# STM32WBA52 register map
File version: 0.1
CPU: CM33 r0p1, little endian, MPU, FPU, 4 interrupt priority bits
Registers are 32-bit, read-write, reset 0x0 unless marked. A register's access mark holds for its fields unless they carry their own. Offsets are from the block's base; [hi:lo] are bit positions.

## RCC (part 1 of 3) — Reset and clock control
Base 0x46020C00
Same registers: SEC_RCC 0x56020C00
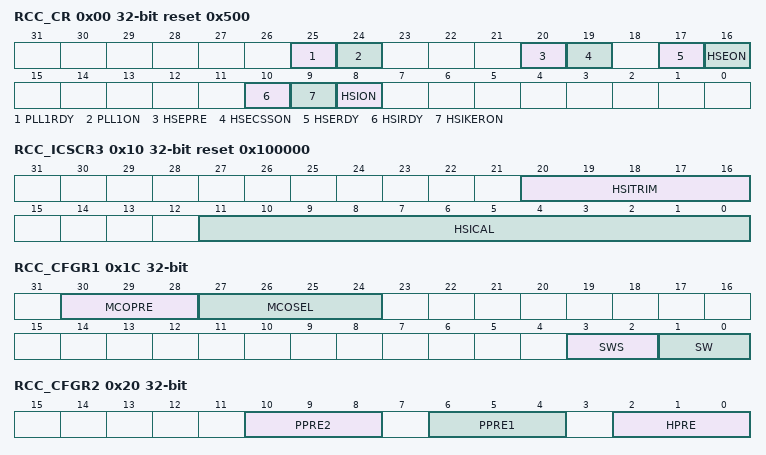
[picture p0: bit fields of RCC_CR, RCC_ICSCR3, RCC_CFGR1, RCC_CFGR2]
0x00 RCC_CR access per field reset 0x500 — RCC clock control register
  [25] PLL1RDY ro — PLL1 clock ready flag Set by hardware to indicate that the PLL1 is locked. Access to the bit can be secured by RCC PLL1SEC. When secure, a non-secure read/write access is RAZ/WI. It does not generate an illegal access interrupt. This bit can be protected against unprivileged access when secure with RCC SPRIV or when non-secure with RCC NSPRIV.
    0=PLL1 unlocked; 1=PLL1 locked (PLL1RDY remains set when PLL1 is selected as sysclk and PLL1 is disabled by HSECSS failure)
  [24] PLL1ON rw — PLL1 enable Set and cleared by software to enable the main PLL. Cleared by hardware when entering Stop or Standby modes and when PLL1 on HSE32 is selected as sysclk, on a HSECSS failure. This bit cannot be reset if the PLL1 clock is used as the system clock. Access to the bit can be secured by RCC PLL1SEC. When secure, a non-secure read/write access is RAZ/WI. It does not generate an illegal access interrupt. This bit can be protected against unprivileged access when secure with RCC SPRIV or when non-secure with RCC NSPRIV.
    0=PLL1 off; 1=PLL1 on
  [20] HSEPRE rw — HSE32 clock for SYSCLK prescaler Set and cleared by software to control the division factor of the HSE32 clock for SYSCLK. Access to the bit can be secured by RCC HSESEC. When secure, a non-secure read/write access is RAZ/WI. It does not generate an illegal access interrupt. This bit can be protected against unprivileged access when secure with RCC SPRIV or when non-secure with RCC NSPRIV.
    0=HSE32 not divided, SYSCLK = HSE32; 1=HSE32 divided, SYSCLK = HSE32/2
  [19] HSECSSON rw — HSE32 clock security system enable Set by software to enable the HSE32 clock security system. When HSECSSON is set, the clock detector is enabled by hardware when the HSE32 oscillator is ready and disabled by hardware if a HSE32 clock failure is detected. This bit is set only and is cleared by reset. Access to the bit can be secured by RCC HSESEC. When secure, a non-secure read/write access is RAZ/WI. It does not generate an illegal access interrupt. This bit can be protected against unprivileged access when secure with RCC SPRIV or when non-secure with RCC NSPRIV.
    0=HSE32 clock security system off (clock detector off); 1=HSE32 clock security system on (clock detector on if the HSE32 oscillator is stable, off if not)
  [17] HSERDY ro — HSE32 clock ready flag Set by hardware to indicate that the HSE32 oscillator is stable. This bit is set both when HSE32 is enabled by software by setting HSEON and when requested as kernel clock by the 2.4 GHz RADIO. Access to the bit can be secured by RCC HSESEC. When secure, a non-secure read/write access is RAZ/WI. It does not generate an illegal access interrupt. This bit can be protected against unprivileged access when secure with RCC SPRIV or when non-secure with RCC NSPRIV.
    0=HSE32 oscillator not ready; 1=HSE32 oscillator ready to be used by the CPU (HSERDY remains set when HSE32 is disabled by HSECSS failure)
  [16] HSEON rw — HSE32 clock enable Set and cleared by software. Cleared by hardware to stop the HSE32 clock for the CPU when entering Stop and Standby modes and on a HSECSS failure. When the HSE32 is used as 2.4 GHz RADIO kernel clock, enabled by RADIOEN and RADIOSMEN and the 2.4 GHz RADIO is active, HSEON is not be cleared when entering low power mode. In this case only Stop 0 mode is entered as low power mode. This bit cannot be reset if the HSE32 oscillator is used directly or indirectly as the system clock. Access to the bit can be secured by RCC HSESEC. When secure, a non-secure read/write access is RAZ/WI. It does not generate an illegal access interrupt. This bit can be protected against unprivileged access when secure with RCC SPRIV or when non-secure with RCC NSPRIV.
    0=HSE32 oscillator not requested by the CPU; 1=HSE32 oscillator ON
  [10] HSIRDY ro — HSI16 clock ready flag Set by hardware to indicate that HSI16 oscillator is stable. This bit is set only when HSI16 is enabled by software by setting HSION. Access to the bit can be secured by RCC HSISEC. When secure, a non-secure read/write access is RAZ/WI. It does not generate an illegal access interrupt. This bit can be protected against unprivileged access when secure with RCC SPRIV or when non-secure with RCC NSPRIV. Note: Once the HSION bit is cleared, HSIRDY goes low after six HSI16 clock cycles.
    0=HSI16 oscillator not ready; 1=HSI16 oscillator ready
  [9] HSIKERON rw — HSI16 enable for some peripheral kernels Set and cleared by software to force HSI16 oscillator on even in Stop modes. Keeping the HSI16 oscillator on in Stop modes allows the communication speed not to be reduced by the HSI16 oscillator startup time. This bit has no effect on register bit HSION value. Cleared by hardware when entering Standby modes. Refer to Peripherals clock gating and autonomous mode for more details. Access to the bit can be secured by RCC HSISEC. When secure, a non-secure read/write access is RAZ/WI. It does not generate an illegal access interrupt. This bit can be protected against unprivileged access when secure with RCC SPRIV or when non-secure with RCC NSPRIV.
    0=No effect on HSI16 oscillator; 1=HSI16 oscillator forced on even in Stop mode
  [8] HSION rw — HSI16 clock enable Set and cleared by software. Cleared by hardware when entering Stop and Standby modes. Set by hardware to force the HSI16 oscillator on when exiting Stop and Standby modes. Set by hardware to force the HSI16 oscillator on in case of clock security failure of the HSE32 crystal oscillator. This bit is set by hardware if the HSI16 is used directly or indirectly as system clock. Access to the bit can be secured by RCC HSISEC. When secure, a non-secure read/write access is RAZ/WI. It does not generate an illegal access interrupt. This bit can be protected against unprivileged access when secure with RCC SPRIV or when non-secure with RCC NSPRIV.
    0=HSI16 oscillator off; 1=HSI16 oscillator on
0x10 RCC_ICSCR3 access per field reset 0x100000 (reset mask 0xFFFFF000) — RCC internal clock sources calibration register 3
  [20:16] HSITRIM rw — HSI16 clock trimming These bits provide an additional user-programmable trimming value that is added to the HSICAL[11:0] bits. It can be programmed to adjust to voltage and temperature variations that influence the frequency of the HSI16.
  [11:0] HSICAL ro — HSI16 clock calibration These bits are initialized at startup with the factory-programmed HSI16 calibration value. When HSITRIM[4:0] is written, HSICAL[11:0] is updated with the sum of HSITRIM[4:0] and the initial factory trim value.
0x1C RCC_CFGR1 access per field — RCC clock configuration register 1
  [30:28] MCOPRE rw — microcontroller clock output prescaler Set and cleared by software. It is highly recommended to change this prescaler before MCO output is enabled. others: not allowed
    0=MCO divided by 1; 1=MCO divided by 2; 2=MCO divided by 4; 3=MCO divided by 8; 4=MCO divided by 16
  [27:24] MCOSEL rw — microcontroller clock output Set and cleared by software. others: reserved Note: This clock output may have some truncated cycles at startup or during MCO clock source switching.
    0=MCO output disabled, no clock on MCO; 1=sysclkpre system clock after PLL1RCLKPRE division selected; 3=HSI16 clock selected; 4=HSE32 clock selected; 5=pll1rclk clock selected; 6=LSI clock selected; 7=LSE clock selected; 8=pll1pclk clock selected; 9=pll1qclk clock selected; 10=hclk5 clock selected
  [3:2] SWS ro — system clock switch status Set and cleared by hardware to indicate which clock source is used as system clock.
    0=HSI16 oscillator used as system clock; 2=HSE32 or HSE32/2, as defined by HSEPRE, used as system clock; 3=pll1rclk used as system clock
  [1:0] SW rw — system clock switch Set and cleared by software to select system clock source (SYSCLK). Cleared by hardware when entering Stop and Standby modes When selecting HSE32 directly or indirectly as system clock and HSE32 oscillator clock security fails, cleared by hardware.
    0=HSI16 selected as system clock; 2=HSE32 or HSE32/2, as defined by HSEPRE, selected as system clock; 3=pll1rclk selected as system clock
0x20 RCC_CFGR2 — RCC clock configuration register 2
  [10:8] PPRE2 — APB2 prescaler Set and cleared by software to control the division factor of the APB2 clock (pclk2). 0xx: pclk2 = hclk1 not divided
    4=pclk2 = hclk1 divided by 2; 5=pclk2 = hclk1 divided by 4; 6=pclk2 = hclk1 divided by 8; 7=pclk2 = hclk1 divided by 16
  [6:4] PPRE1 — APB1 prescaler Set and cleared by software to control the division factor of the APB1 clock (pclk1). 0xx: pclk1 = hclk1 not divided
    4=pclk1 = hclk1 divided by 2; 5=pclk1 = hclk1 divided by 4; 6=pclk1 = hclk1 divided by 8; 7=pclk1 = hclk1 divided by 16
  [2:0] HPRE — AHB1, AHB2 and AHB4 prescaler Set and cleared by software to control the division factor of the AHB1, AHB2 and AHB4 clock (hclk1). The software must limit the incremental frequency step by setting these bits correctly to ensure that the hclk1 maximum incremental frequency step does not exceed the maximum allowed incremental frequency step (for more details, refer to Table�99: SYSCLK and bus maximum frequency). After a write operation to these bits and before decreasing the voltage range, this register must be read to be sure that the new value is taken into account. 0xx: hclk1 = SYSCLK not divided
    4=hclk1 = SYSCLK divided by 2; 5=hclk1 = SYSCLK divided by 4; 6=hclk1 = SYSCLK divided by 8; 7=hclk1 = SYSCLK divided by 16
0x24 RCC_CFGR3 — RCC clock configuration register 3
  [6:4] PPRE7 — APB7 prescaler Set and cleared by software to control the division factor of the APB7 clock (pclk7). 0xx: hclk1 not divided
    4=hclk1 divided by 2; 5=hclk1 divided by 4; 6=hclk1 divided by 8; 7=hclk1 divided by 16
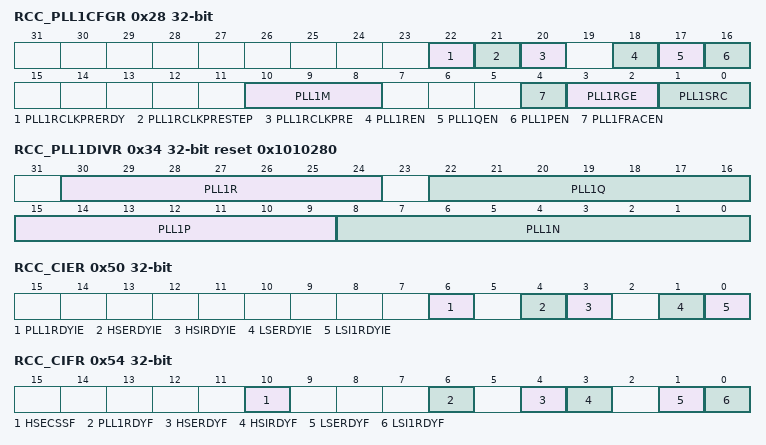
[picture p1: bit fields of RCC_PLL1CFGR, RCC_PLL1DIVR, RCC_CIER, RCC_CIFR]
0x28 RCC_PLL1CFGR access per field — RCC PLL1 configuration register
  [22] PLL1RCLKPRERDY ro — pll1rclkpre not divided ready. Set by hardware after PLL1RCLKPRE has been set from divided to not divide, to indicate that the pll1rclk not divided is available on sysclkpre.
    0=pll1rclk divided; 1=pll1rclk not divided ready
  [21] PLL1RCLKPRESTEP rw — pll1rclk clock for SYSCLK prescaler division step selection Set and cleared by software to control the division step of the pll1rclk clock for SYSCLK.
    0=pll1rclk 2-step division; 1=pll1rclk 3-step division
  [20] PLL1RCLKPRE rw — pll1rclk clock for SYSCLK prescaler division enable Set and cleared by software to control the division of the pll1rclk clock for SYSCLK.
    0=pll1rclk not divided, sysclkpre = pll1rclk; 1=pll1rclk divided, sysclkpre = pll1rclk divided
  [18] PLL1REN rw — PLL1 DIVR divider output enable Set and cleared by software to enable the pll1rclk output of the PLL1. To save power, PLL1REN and PLL1R bits must be set to 0 when the pll1rclk is not used. This bit can be written only when the PLL1 is disabled (PLL1ON = 0 and PLL1RDY = 0).
    0=pll1rclk output disabled; 1=pll1rclk output enabled
  [17] PLL1QEN rw — PLL1 DIVQ divider output enable Set and reset by software to enable the pll1qclk output of the PLL1. To save power, PLL1QEN and PLL1Q bits must be set to 0 when the pll1qclk is not used. This bit can be written only when the PLL1 is disabled (PLL1ON = 0 and PLL1RDY = 0).
    0=pll1qclk output disabled; 1=pll1qclk output enabled
  [16] PLL1PEN rw — PLL1 DIVP divider output enable Set and reset by software to enable the pll1pclk output of the PLL1. To save power, PLL1PEN and PLL1P bits must be set to 0 when the pll1pclk is not used. This bit can be written only when the PLL1 is disabled (PLL1ON = 0 and PLL1RDY = 0).
    0=pll1pclk output disabled; 1=pll1pclk output enabled
  [10:8] PLL1M rw — Prescaler for PLL1 Set and cleared by software to configure the prescaler of the PLL1. The VCO1 input frequency is PLL1 input clock frequency/PLL1M. This bit can be written only when the PLL1 is disabled (PLL1ON = 0 and PLL1RDY = 0). ...
    0=division by 1 (bypass); 1=division by 2; 2=division by 3; 7=division by 8
  [4] PLL1FRACEN rw — PLL1 fractional latch enable Set and reset by software to latch the content of PLL1FRACN into the ΣΔ modulator. In order to latch the PLL1FRACN value into the ΣΔ modulator, PLL1FRACEN must be set to 0, then set to 1: the transition 0 to 1 transfers the content of PLL1FRACN into the modulator (see PLL1 initialization phase for details).
  [3:2] PLL1RGE rw — PLL1 input frequency range Set and reset by software to select the proper reference frequency range used for PLL1. This bit must be written before enabling the PLL1. 00-01-10: PLL1 input (ref1_ck) clock range frequency between 4 and 8 MHz
    3=PLL1 input (ref1_ck) clock range frequency between 8 and 16 MHz
  [1:0] PLL1SRC rw — PLL1 entry clock source Set and cleared by software to select PLL1 clock source. These bits can be written only when the PLL1 is disabled. Cleared by hardware when entering Stop or Standby modes. Note: In order to save power, when no PLL1 clock is used, the value of PLL1SRC must be 0.
    0=no clock sent to PLL1; 2=HSI16 clock selected as PLL1 clock entry; 3=HSE32 clock after HSEPRE divider selected as PLL1 clock entry
0x34 RCC_PLL1DIVR reset 0x1010280 — RCC PLL1 dividers register
  [30:24] PLL1R — PLL1 DIVR division factor Set and reset by software to control the frequency of the pll1rclk clock. These bits can be written only when the PLL1 is disabled (PLL1ON = 0 and PLL1RDY = 0). ...
    0=pll1rclk = VCO output frequency; 1=pll1rclk = VCO output frequency / 2 (default after reset); 2=pll1rclk = VCO output frequency / 3; 3=pll1rclk = VCO output frequency / 4; 127=pll1rclk = VCO output frequency / 128
  [22:16] PLL1Q — PLL1 DIVQ division factor Set and reset by software to control the frequency of the PLl1QCLK clock. These bits can be written only when the PLL1 is disabled (PLL1ON = 0 and PLL1RDY = 0). ...
    0=PLl1QCLK = VCO output frequency; 1=PLl1QCLK = VCO output frequency / 2 (default after reset); 2=PLl1QCLK = VCO output frequency / 3; 3=PLl1QCLK = VCO output frequency / 4; 127=PLl1QCLK = VCO output frequency / 128
  [15:9] PLL1P — PLL1 DIVP division factor Set and reset by software to control the frequency of the pll1pclk clock. These bits can be written only when the PLL1 is disabled (PLL1ON = 0 and PLL1RDY = 0). Note that odd division factors are not allowed. ...
    0=Not allowed; 1=pll1pclk = VCO output frequency / 2 (default after reset); 2=not allowed; 3=pll1pclk = VCO output frequency / 4; 127=pll1pclk = VCO output frequency / 128
  [8:0] PLL1N — Multiplication factor for PLL1 VCO Set and reset by software to control the multiplication factor of the VCO. These bits can be written only when the PLL1 is disabled (PLL1ON = 0 and PLL1RDY = 0). ... ... others: reserved VCO output frequency = F<sub>ref1_ck</sub> x multiplication factor for PLL1 VCO, when fractional value 0 has been loaded into PLL1FRACN, with: Multiplication factor for PLL1 VCO between 4 and 512 input frequency F<sub>ref1_ck</sub> between 4 and 16�MHz
    3=multiplication factor for PLL1 VCO= 4; 4=multiplication factor for PLL1 VCO = 5; 5=multiplication factor for PLL1 VCO = 6; 128=multiplication factor for PLL1 VCO = 129 (default after reset); 0x1FF=multiplication factor for PLL1 VCO = 512
0x38 RCC_PLL1FRACR — RCC PLL1 fractional divider register
  [15:3] PLL1FRACN — Fractional part of the multiplication factor for PLL1 VCO Set and reset by software to control the fractional part of the multiplication factor of the VCO. These bits can be written at any time, allowing dynamic fine-tuning of the PLL1 VCO. VCO output frequency = F<sub>ref1_ck</sub> x [multiplication factor for PLL1 VCO + (PLL1FRACN / 2<sup>13</sup>)], with: Multiplication factor for PLL1 VCO must be between 4 and 512. PLL1FRACN can be between 0 and 2<sup>13</sup>- 1. The input frequency F<sub>ref1_ck</sub> must be between 4 and 16 MHz. To change the used fractional value on-the-fly even if the PLL1 is enabled, the application must proceed as follows: Set the bit PLL1FRACEN to 0. Write the new fractional value into PLL1FRACN. Set the bit PLL1FRACEN to 1.
0x50 RCC_CIER — RCC clock interrupt enable register
  [6] PLL1RDYIE — PLL1 ready interrupt enable Set and cleared by software to enable/disable interrupt caused by PLL1 lock. Access to the bit can be secured by RCC PLL1SEC. When secure, a non-secure read/write access is RAZ/WI. It does not generate an illegal access interrupt. This bit can be protected against unprivileged access when secure with RCC SPRIV or when non-secure with RCC NSPRIV.
    0=PLL1 lock interrupt disabled; 1=PLL1 lock interrupt enabled
  [4] HSERDYIE — HSE32 ready interrupt enable Set and cleared by software to enable/disable interrupt caused by the HSE32 oscillator stabilization. Access to the bit can be secured by RCC HSESEC. When secure, a non-secure read/write access is RAZ/WI. It does not generate an illegal access interrupt. This bit can be protected against unprivileged access when secure with RCC SPRIV or when non-secure with RCC NSPRIV.
    0=HSE32 ready interrupt disabled; 1=HSE32 ready interrupt enabled
  [3] HSIRDYIE — HSI16 ready interrupt enable Set and cleared by software to enable/disable interrupt caused by the HSI16 oscillator stabilization. Access to the bit can be secured by RCC HSISEC. When secure, a non-secure read/write access is RAZ/WI. It does not generate an illegal access interrupt. This bit can be protected against unprivileged access when secure with RCC SPRIV or when non-secure with RCC NSPRIV.
    0=HSI16 ready interrupt disabled; 1=HSI16 ready interrupt enabled
  [1] LSERDYIE — LSE ready interrupt enable Set and cleared by software to enable/disable interrupt caused by the LSE oscillator stabilization. Access to the bit can be secured by RCC LSESEC. When secure, a non-secure read/write access is RAZ/WI. It does not generate an illegal access interrupt. This bit can be protected against unprivileged access when secure with RCC SPRIV or when non-secure with RCC NSPRIV.
    0=LSE ready interrupt disabled; 1=LSE ready interrupt enabled
  [0] LSI1RDYIE — LSI1 ready interrupt enable Set and cleared by software to enable/disable interrupt caused by the LSI1 oscillator stabilization. Access to the bit can be secured by RCC LSISEC. When secure, a non-secure read/write access is RAZ/WI. It does not generate an illegal access interrupt. This bit can be protected against unprivileged access when secure with RCC SPRIV or when non-secure with RCC NSPRIV.
    0=LSI1 ready interrupt disabled; 1=LSI1 ready interrupt enabled
0x54 RCC_CIFR ro — RCC clock interrupt flag register
  [10] HSECSSF — HSE32 clock security system interrupt flag Set by hardware when a clock security failure is detected in the HSE32 oscillator. Cleared by software setting the HSECSSC bit. Access to the bit can be secured by RCC HSESEC. When secure, a non-secure read/write access is RAZ/WI. It does not generate an illegal access interrupt. This bit can be protected against unprivileged access when secure with RCC SPRIV or when non-secure with RCC NSPRIV.
    0=no clock security interrupt caused by HSE32 clock failure; 1=clock security interrupt caused by HSE32 clock failure
  [6] PLL1RDYF — PLL1 ready interrupt flag Set by hardware when the PLL1 locks and PLL1RDYIE is set. Cleared by software setting the PLL1RDYC bit. Access to the bit can be secured by RCC PLL1SEC. When secure, a non-secure read/write access is RAZ/WI. It does not generate an illegal access interrupt. This bit can be protected against unprivileged access when secure with RCC SPRIV or when non-secure with RCC NSPRIV.
    0=no clock ready interrupt caused by PLL1 lock; 1=clock ready interrupt caused by PLL1 lock
  [4] HSERDYF — HSE32 ready interrupt flag Set by hardware when the HSE32 clock becomes stable and HSERDYIE is set. Cleared by software setting the HSERDYC bit. Access to the bit can be secured by RCC HSESEC. When secure, a non-secure read/write access is RAZ/WI. It does not generate an illegal access interrupt. This bit can be protected against unprivileged access when secure with RCC SPRIV or when non-secure with RCC NSPRIV.
    0=no clock ready interrupt caused by the HSE32 oscillator; 1=clock ready interrupt caused by the HSE32 oscillator
  [3] HSIRDYF — HSI16 ready interrupt flag Set by hardware when the HSI16 clock becomes stable and HSIRDYIE is set in a response to setting the HSION (see RCC_CR). When HSION is not set but the HSI16 oscillator is enabled by the peripheral through a clock request, this bit is not set and no interrupt is generated. Access to the bit can be secured by RCC HSISEC. When secure, a non-secure read/write access is RAZ/WI. It does not generate an illegal access interrupt. This bit can be protected against unprivileged access when secure with RCC SPRIV or when non-secure with RCC NSPRIV. Cleared by software setting the HSIRDYC bit.
    0=no clock ready interrupt caused by the HSI16 oscillator; 1=clock ready interrupt caused by the HSI16 oscillator
  [1] LSERDYF — LSE ready interrupt flag Set by hardware when the LSE clock becomes stable and LSERDYIE is set. Cleared by software setting the LSERDYC bit. Access to the bit can be secured by RCC LSESEC. When secure, a non-secure read/write access is RAZ/WI. It does not generate an illegal access interrupt. This bit can be protected against unprivileged access when secure with RCC SPRIV or when non-secure with RCC NSPRIV.
    0=no clock ready interrupt caused by the LSE oscillator; 1=clock ready interrupt caused by the LSE oscillator
  [0] LSI1RDYF — LSI1 ready interrupt flag Set by hardware when the LSI1 clock becomes stable and LSI1RDYIE is set. Cleared by software setting the LSI1RDYC bit. Access to the bit can be secured by RCC LSISEC. When secure, a non-secure read/write access is RAZ/WI. It does not generate an illegal access interrupt. This bit can be protected against unprivileged access when secure with RCC SPRIV or when non-secure with RCC NSPRIV.
    0=no clock ready interrupt caused by the LSI1 oscillator; 1=clock ready interrupt caused by the LSI1 oscillator
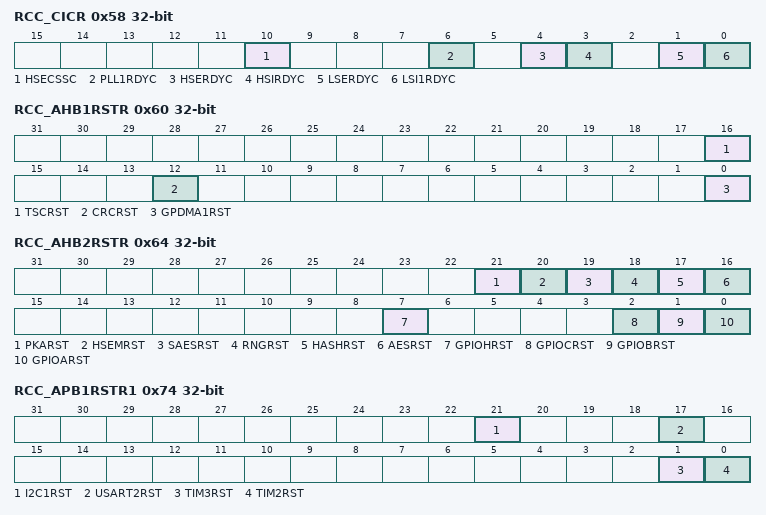
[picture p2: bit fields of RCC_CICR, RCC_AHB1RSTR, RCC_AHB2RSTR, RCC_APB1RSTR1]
0x58 RCC_CICR wo — RCC clock interrupt clear register
  [10] HSECSSC — High speed external clock security system interrupt clear Writing this bit to 1 clears the HSECSSF flag. Writing 0 has no effect. Access to the bit can be secured by RCC HSESEC. When secure, a non-secure read/write access is RAZ/WI. It does not generate an illegal access interrupt. This bit can be protected against unprivileged access when secure with RCC SPRIV or when non-secure with RCC NSPRIV.
  [6] PLL1RDYC — PLL1 ready interrupt clear Writing this bit to 1 clears the PLL1RDYF flag. Writing 0 has no effect. Access to the bit can be secured by RCC PLL1SEC. When secure, a non-secure read/write access is RAZ/WI. It does not generate an illegal access interrupt. This bit can be protected against unprivileged access when secure with RCC SPRIV or when non-secure with RCC NSPRIV.
  [4] HSERDYC — HSE32 ready interrupt clear Writing this bit to 1 clears the HSERDYF flag. Writing 0 has no effect. Access to the bit can be secured by RCC HSESEC. When secure, a non-secure read/write access is RAZ/WI. It does not generate an illegal access interrupt. This bit can be protected against unprivileged access when secure with RCC SPRIV or when non-secure with RCC NSPRIV.
  [3] HSIRDYC — HSI16 ready interrupt clear Writing this bit to 1 clears the HSIRDYF flag. Writing 0 has no effect.\ Access to the bit can be secured by RCC HSISEC. When secure, a non-secure read/write access is RAZ/WI. It does not generate an illegal access interrupt. This bit can be protected against unprivileged access when secure with RCC SPRIV or when non-secure with RCC NSPRIV.
  [1] LSERDYC — LSE ready interrupt clear Writing this bit to 1 clears the LSERDYF flag. Writing 0 has no effect. Access to the bit can be secured by RCC LSESEC. When secure, a non-secure read/write access is RAZ/WI. It does not generate an illegal access interrupt. This bit can be protected against unprivileged access when secure with RCC SPRIV or when non-secure with RCC NSPRIV.
  [0] LSI1RDYC — LSI1 ready interrupt clear Writing this bit to 1 clears the LSI1RDYF flag. Writing 0 has no effect. Access to the bit can be secured by RCC LSISEC. When secure, a non-secure read/write access is RAZ/WI. It does not generate an illegal access interrupt. This bit can be protected against unprivileged access when secure with RCC SPRIV or when non-secure with RCC NSPRIV.
0x60 RCC_AHB1RSTR — RCC AHB1 peripheral reset register
  [16] TSCRST — TSC reset Set and cleared by software. Access can be secured by GTZC_TZSC TSCSEC. When secure, a non-secure read/write access is RAZ/WI. It does not generate an illegal access interrupt. This bit can be protected against unprivileged access when secure with RCC SPRIV or when non-secure with RCC NSPRIV.
    0=No effect; 1=Reset TSC
  [12] CRCRST — CRC reset Set and cleared by software. Access can be secured by GTZC_TZSC CRCSEC. When secure, a non-secure read/write access is RAZ/WI. It does not generate an illegal access interrupt. This bit can be protected against unprivileged access when secure with RCC SPRIV or when non-secure with RCC NSPRIV.
    0=No effect; 1=Reset CRC
  [0] GPDMA1RST — GPDMA1 reset Set and cleared by software. Access can be secured by GPDMA1 SECx. When secure, a non-secure read/write access is RAZ/WI. It does not generate an illegal access interrupt. This bit can be protected against unprivileged access when secure with RCC SPRIV or when non-secure with RCC NSPRIV.
    0=No effect; 1=Reset GPDMA1
0x64 RCC_AHB2RSTR — RCC AHB2 peripheral reset register
  [21] PKARST — PKA reset Set and cleared by software. Access can be secured by GTZC_TZSC PKASEC. When secure, a non-secure read/write access is RAZ/WI. It does not generate an illegal access interrupt. This bit can be protected against unprivileged access when secure with RCC SPRIV or when non-secure with RCC NSPRIV.
    0=No effect; 1=Reset PKA
  [20] HSEMRST — HSEM hardware accelerator reset Set and cleared by software. Can only be accessed secure when one or more features in the HSEM is secure. When secure, a non-secure read/write access is RAZ/WI. It does not generate an illegal access interrupt. This bit can be protected against unprivileged access when secure with RCC SPRIV or when non-secure with RCC NSPRIV.
    0=No effect; 1=Reset HSEM
  [19] SAESRST — SAES hardware accelerator reset Set and cleared by software. Access can be secured by GTZC_TZSC SAESSEC. When secure, a non-secure read/write access is RAZ/WI. It does not generate an illegal access interrupt. This bit can be protected against unprivileged access when secure with RCC SPRIV or when non-secure with RCC NSPRIV.
    0=No effect; 1=Reset SAES
  [18] RNGRST — Random number generator reset Set and cleared by software. Access can be secured by GTZC_TZSC RNGSEC. When secure, a non-secure read/write access is RAZ/WI. It does not generate an illegal access interrupt. This bit can be protected against unprivileged access when secure with RCC SPRIV or when non-secure with RCC NSPRIV.
    0=No effect; 1=Reset RNG
  [17] HASHRST — Hash reset Set and cleared by software. Access can be secured by GTZC_TZSC HASHSEC. When secure, a non-secure read/write access is RAZ/WI. It does not generate an illegal access interrupt. This bit can be protected against unprivileged access when secure with RCC SPRIV or when non-secure with RCC NSPRIV.
    0=No effect; 1=Reset HASH
  [16] AESRST — AES hardware accelerator reset Set and cleared by software. Access can be secured by GTZC_TZSC AESSEC. When secure, a non-secure read/write access is RAZ/WI. It does not generate an illegal access interrupt. This bit can be protected against unprivileged access when secure with RCC SPRIV or when non-secure with RCC NSPRIV.
    0=No effect; 1=Reset AES
  [7] GPIOHRST — IO port H reset Set and cleared by software. Access can be secured by GPIOH SECx. When secure, a non-secure read/write access is RAZ/WI. It does not generate an illegal access interrupt. This bit can be protected against unprivileged access when secure with RCC SPRIV or when non-secure with RCC NSPRIV.
    0=No effect; 1=Reset IO port H
  [2] GPIOCRST — IO port C reset Set and cleared by software. Access can be secured by GPIOC SECx. When secure, a non-secure read/write access is RAZ/WI. It does not generate an illegal access interrupt. This bit can be protected against unprivileged access when secure with RCC SPRIV or when non-secure with RCC NSPRIV.
    0=No effect; 1=Reset IO port C
  [1] GPIOBRST — IO port B reset Set and cleared by software. Access can be secured by GPIOB SECx. When secure, a non-secure read/write access is RAZ/WI. It does not generate an illegal access interrupt. This bit can be protected against unprivileged access when secure with RCC SPRIV or when non-secure with RCC NSPRIV.
    0=No effect; 1=Reset IO port B
  [0] GPIOARST — IO port A reset Set and cleared by software. Access can be secured by GPIOA SECx. When secure, a non-secure read/write access is RAZ/WI. It does not generate an illegal access interrupt. This bit can be protected against unprivileged access when secure with RCC SPRIV or when non-secure with RCC NSPRIV.
    0=No effect; 1=Reset IO port A
0x6C RCC_AHB4RSTR — RCC AHB4 peripheral reset register
  [5] ADC4RST — ADC4 reset Set and cleared by software. Access can be secred by GTZC_TZSC ADC4SEC. When secure, a non-secure read/write access is RAZ/WI. It does not generate an illegal access interrupt. This bit can be protected against unprivileged access when secure with RCC SPRIV or when non-secure with RCC NSPRIV.
    0=No effect; 1=Reset ADC4 interface
0x70 RCC_AHB5RSTR — RCC AHB5 peripheral reset register
  [0] RADIORST — 2.4 GHz RADIO reset Set and cleared by software. Access can be secured by GTZC_TZSC RADIOSEC. When secure, a non-secure read/write access is RAZ/WI. It does not generate an illegal access interrupt. This bit can be protected against unprivileged access when secure with RCC SPRIV or when non-secure with RCC NSPRIV.
    0=No effect; 1=Reset 2.4 GHz RADIO
0x74 RCC_APB1RSTR1 — RCC APB1 peripheral reset register 1
  [21] I2C1RST — I2C1 reset Set and cleared by software. Access can be secured by GTZC_TZSC I2C1SEC. When secure, a non-secure read/write access is RAZ/WI. It does not generate an illegal access interrupt. This bit can be protected against unprivileged access when secure with RCC SPRIV or when non-secure with RCC NSPRIV.
    0=No effect; 1=Reset I2C1
  [17] USART2RST — USART2 reset Set and cleared by software. Access can be secured by GTZC_TZSC UART2SEC. When secure, a non-secure read/write access is RAZ/WI. It does not generate an illegal access interrupt. This bit can be protected against unprivileged access when secure with RCC SPRIV or when non-secure with RCC NSPRIV.
    0=No effect; 1=Reset USART2
  [1] TIM3RST — TIM3 reset Set and cleared by software. Access can be secured by GTZC_TZSC TIM3SEC. When secure, a non-secure read/write access is RAZ/WI. It does not generate an illegal access interrupt. This bit can be protected against unprivileged access when secure with RCC SPRIV or when non-secure with RCC NSPRIV.
    0=No effect; 1=Reset TIM3
  [0] TIM2RST — TIM2 reset Set and cleared by software. Access can be secured by GTZC_TZSC TIM2SEC. When secure, a non-secure read/write access is RAZ/WI. It does not generate an illegal access interrupt. This bit can be protected against unprivileged access when secure with RCC SPRIV or when non-secure with RCC NSPRIV.
    0=No effect; 1=Reset TIM2
0x78 RCC_APB1RSTR2 — RCC APB1 peripheral reset register 2
  [5] LPTIM2RST — LPTIM2 reset Set and cleared by software. Access can be secured by GTZC_TZSC LPTIM2SEC. When secure, a non-secure read/write access is RAZ/WI. It does not generate an illegal access interrupt. This bit can be protected against unprivileged access when secure with RCC SPRIV or when non-secure with RCC NSPRIV.
    0=No effect; 1=Reset LPTIM2
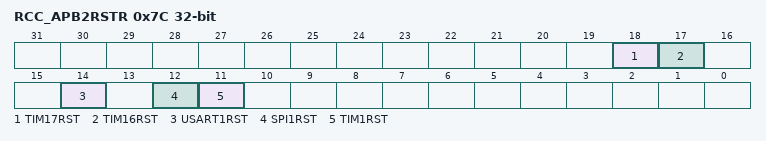
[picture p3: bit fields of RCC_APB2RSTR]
0x7C RCC_APB2RSTR — RCC APB2 peripheral reset register
  [18] TIM17RST — TIM17 reset Set and cleared by software. Access can be secured by GTZC_TZSC TIM17SEC. When secure, a non-secure read/write access is RAZ/WI. It does not generate an illegal access interrupt. This bit can be protected against unprivileged access when secure with RCC SPRIV or when non-secure with RCC NSPRIV.
    0=No effect; 1=Reset TIM17
  [17] TIM16RST — TIM16 reset Set and cleared by software. Access can be secured by GTZC_TZSC TIM16SEC. When secure, a non-secure read/write access is RAZ/WI. It does not generate an illegal access interrupt. This bit can be protected against unprivileged access when secure with RCC SPRIV or when non-secure with RCC NSPRIV.
    0=No effect; 1=Reset TIM16
  [14] USART1RST — USART1 reset Set and cleared by software. Access can be secured by GTZC_TZSC USART1SEC. When secure, a non-secure read/write access is RAZ/WI. It does not generate an illegal access interrupt. This bit can be protected against unprivileged access when secure with RCC SPRIV or when non-secure with RCC NSPRIV.
    0=No effect; 1=Reset USART1
  [12] SPI1RST — SPI1 reset Set and cleared by software. Access can be secured by GTZC_TZSC SPI1SEC. When secure, a non-secure read/write access is RAZ/WI. It does not generate an illegal access interrupt. This bit can be protected against unprivileged access when secure with RCC SPRIV or when non-secure with RCC NSPRIV.
    0=No effect; 1=Reset SPI1
  [11] TIM1RST — TIM1 reset Set and cleared by software. Access can be secured by GTZC_TZSC TIM1SEC. When secure, a non-secure read/write access is RAZ/WI. It does not generate an illegal access interrupt. This bit can be protected against unprivileged access when secure with RCC SPRIV or when non-secure with RCC NSPRIV.
    0=No effect; 1=Reset TIM1
